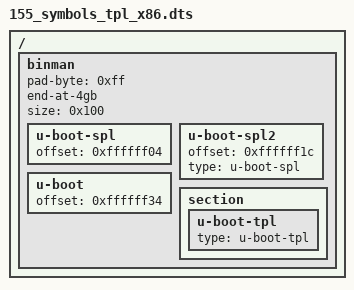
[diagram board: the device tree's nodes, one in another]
/* SPDX-License-Identifier: GPL-2.0+ */
/dts-v1/;

/ {
	#address-cells = <1>;
	#size-cells = <1>;

	binman {
		pad-byte = <0xff>;
		end-at-4gb;
		size = <0x100>;
		u-boot-spl {
			offset = <0xffffff04>;
		};

		u-boot-spl2 {
			offset = <0xffffff1c>;
			type = "u-boot-spl";
		};

		u-boot {
			offset = <0xffffff34>;
		};

		section {
			u-boot-tpl {
				type = "u-boot-tpl";
			};
		};
	};
};
